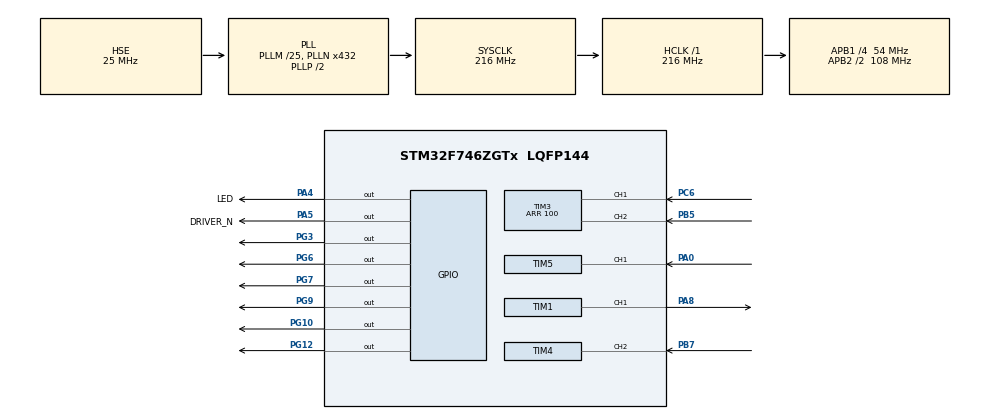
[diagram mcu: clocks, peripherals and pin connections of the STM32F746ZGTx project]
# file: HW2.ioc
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Mcu.Family=STM32F7
Mcu.Name=STM32F746ZGTx
Mcu.Package=LQFP144
NVIC.PriorityGroup=NVIC_PRIORITYGROUP_4
NVIC.TIM1_CC_IRQn=true\:0\:0\:false\:false\:true\:true\:true
NVIC.TIM1_UP_TIM10_IRQn=true\:0\:0\:false\:false\:true\:true\:true
NVIC.TIM2_IRQn=true\:0\:0\:false\:false\:true\:true\:true
NVIC.TIM4_IRQn=true\:0\:0\:false\:false\:true\:true\:true
NVIC.TIM5_IRQn=true\:0\:0\:false\:false\:true\:true\:true
PA0/WKUP.Signal=S_TIM5_CH1
PA4.GPIO_Label=LED
PA4.Signal=GPIO_Output
PA5.GPIO_Label=DRIVER_N
PA5.Signal=GPIO_Output
PA8.Signal=S_TIM1_CH1
PB5.Signal=S_TIM3_CH2
PB7.Signal=S_TIM4_CH2
PC6.Signal=S_TIM3_CH1
PG10.Signal=GPIO_Output
PG12.Signal=GPIO_Output
PG3.Signal=GPIO_Output
PG6.Signal=GPIO_Output
PG7.Signal=GPIO_Output
PG9.Signal=GPIO_Output
PH0/OSC_IN.Mode=HSE-External-Oscillator
PH0/OSC_IN.Signal=RCC_OSC_IN
PH1/OSC_OUT.Mode=HSE-External-Oscillator
PH1/OSC_OUT.Signal=RCC_OSC_OUT
ProjectManager.HeapSize=0x200
ProjectManager.StackSize=0x400
ProjectManager.TargetToolchain=MDK-ARM V5.27
RCC.AHBFreq_Value=216000000
RCC.APB1CLKDivider=RCC_HCLK_DIV4
RCC.APB1Freq_Value=54000000
RCC.APB1TimFreq_Value=108000000
RCC.APB2CLKDivider=RCC_HCLK_DIV2
RCC.APB2Freq_Value=108000000
RCC.APB2TimFreq_Value=216000000
RCC.CortexFreq_Value=216000000
RCC.HCLKFreq_Value=216000000
RCC.HSE_VALUE=25000000
RCC.HSI_VALUE=16000000
RCC.LSE_VALUE=32768
RCC.PLLM=25
RCC.PLLN=432
RCC.PLLSourceVirtual=RCC_PLLSOURCE_HSE
RCC.SYSCLKFreq_VALUE=216000000
RCC.SYSCLKSource=RCC_SYSCLKSOURCE_PLLCLK
RCC.USBFreq_Value=216000000
RCC.VCOOutputFreq_Value=432000000
SH.S_TIM1_CH1.0=TIM1_CH1,PWM Generation1 CH1
SH.S_TIM3_CH1.0=TIM3_CH1,Encoder_Interface
SH.S_TIM3_CH2.0=TIM3_CH2,Encoder_Interface
SH.S_TIM4_CH2.0=TIM4_CH2,Input_Capture2_from_TI2
SH.S_TIM5_CH1.0=TIM5_CH1,Input_Capture1_from_TI1
TIM1.AutoReloadPreload=TIM_AUTORELOAD_PRELOAD_DISABLE
TIM1.Channel-PWM\ Generation1\ CH1=TIM_CHANNEL_1
TIM1.Period=100-1
TIM1.Prescaler=108-1
TIM1.Pulse-PWM\ Generation1\ CH1=50
TIM2.Period=999
TIM2.Prescaler=10799
TIM3.AutoReloadPreload=TIM_AUTORELOAD_PRELOAD_ENABLE
TIM3.Period=100
TIM4.Channel-Input_Capture2_from_TI2=TIM_CHANNEL_2
TIM4.Period=40000-1
TIM4.Prescaler=1080-1
TIM5.Channel-Input_Capture1_from_TI1=TIM_CHANNEL_1
TIM5.Period=40000-1
TIM5.Prescaler=1080-1
VP_TIM1_VS_ClockSourceINT.Mode=Internal
VP_TIM2_VS_ClockSourceINT.Mode=Internal
VP_TIM4_VS_ClockSourceINT.Mode=Internal
VP_TIM5_VS_ClockSourceINT.Mode=Internal
board=custom

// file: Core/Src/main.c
/* USER CODE BEGIN Header */
/**
  ******************************************************************************
  * @file           : main.c
  * @brief          : Main program body
  ******************************************************************************
  * @attention
  *
  * <h2><center>&copy; Copyright (c) 2021 STMicroelectronics.
  * All rights reserved.</center></h2>
  *
  * This software component is licensed by ST under BSD 3-Clause license,
  * the "License"; You may not use this file except in compliance with the
  * License. You may obtain a copy of the License at:
  *                        opensource.org/licenses/BSD-3-Clause
  *
  ******************************************************************************
  */
/* USER CODE END Header */
#include "main.h"
#include "tim.h"
#include "gpio.h"

void SystemClock_Config(void);

int main(void)
{

  /* MCU Configuration--------------------------------------------------------*/

  /* Reset of all peripherals, Initializes the Flash interface and the Systick. */
  HAL_Init();

  /* Configure the system clock */
  SystemClock_Config();

  /* Initialize all configured peripherals */
  MX_GPIO_Init();
  MX_TIM1_Init();
  MX_TIM2_Init();
  MX_TIM3_Init();
  MX_TIM4_Init();
  MX_TIM5_Init();
  /* USER CODE BEGIN 2 */
	//HAL_TIM_Base_Start_IT(&htim1);
	HAL_TIM_Base_Start_IT(&htim5);
//Turn on input capture interrupt, set drop edge to trigger interrupt
//__HAL_TIM_SET_CAPTUREPOLARITY(&htim4, TIM_CHANNEL_2, TIM_INPUTCHANNELPOLARITY_RISING);
	HAL_TIM_IC_Start_IT(&htim5, TIM_CHANNEL_1);    //Start Input Capture
	HAL_TIM_Base_Start_IT(&htim4);
	HAL_TIM_IC_Start_IT(&htim4, TIM_CHANNEL_2);
	__HAL_TIM_CLEAR_IT(&htim3,TIM_IT_UPDATE);
	__HAL_TIM_ENABLE_IT(&htim3,TIM_IT_UPDATE);
	HAL_TIM_Base_Start_IT(&htim1);
	HAL_TIM_Base_Start_IT(&htim2);
	HAL_TIM_PWM_Start_IT(&htim1,TIM_CHANNEL_1);
	HAL_TIM_Encoder_Start(&htim3, TIM_CHANNEL_ALL);
	HAL_TIM_OC_Start_IT(&htim1,TIM_CHANNEL_1);
	//HAL_TIM_IC_Start_IT(&htim4,TIM_CHANNEL_2);
	HAL_GPIO_WritePin(DRIVER_N_GPIO_Port,DRIVER_N_Pin,GPIO_PIN_RESET);
  /* USER CODE END 2 */

  /* Infinite loop */
  while (1)
  {

    /* USER CODE BEGIN 3 */
//		HAL_GPIO_TogglePin(LED_GPIO_Port,LED_Pin);
//		HAL_Delay(500);
  }
  /* USER CODE END 3 */
}

void SystemClock_Config(void)
{
  RCC_OscInitTypeDef RCC_OscInitStruct = {0};
  RCC_ClkInitTypeDef RCC_ClkInitStruct = {0};

  /** Configure the main internal regulator output voltage
  */
  __HAL_RCC_PWR_CLK_ENABLE();
  __HAL_PWR_VOLTAGESCALING_CONFIG(PWR_REGULATOR_VOLTAGE_SCALE1);
  /** Initializes the RCC Oscillators according to the specified parameters
  * in the RCC_OscInitTypeDef structure.
  */
  RCC_OscInitStruct.OscillatorType = RCC_OSCILLATORTYPE_HSE;
  RCC_OscInitStruct.HSEState = RCC_HSE_ON;
  RCC_OscInitStruct.PLL.PLLState = RCC_PLL_ON;
  RCC_OscInitStruct.PLL.PLLSource = RCC_PLLSOURCE_HSE;
  RCC_OscInitStruct.PLL.PLLM = 25;
  RCC_OscInitStruct.PLL.PLLN = 432;
  RCC_OscInitStruct.PLL.PLLP = RCC_PLLP_DIV2;
  RCC_OscInitStruct.PLL.PLLQ = 2;
  if (HAL_RCC_OscConfig(&RCC_OscInitStruct) != HAL_OK)
  {
    Error_Handler();
  }
  /** Activate the Over-Drive mode
  */
  if (HAL_PWREx_EnableOverDrive() != HAL_OK)
  {
    Error_Handler();
  }
  /** Initializes the CPU, AHB and APB buses clocks
  */
  RCC_ClkInitStruct.ClockType = RCC_CLOCKTYPE_HCLK|RCC_CLOCKTYPE_SYSCLK
                              |RCC_CLOCKTYPE_PCLK1|RCC_CLOCKTYPE_PCLK2;
  RCC_ClkInitStruct.SYSCLKSource = RCC_SYSCLKSOURCE_PLLCLK;
  RCC_ClkInitStruct.AHBCLKDivider = RCC_SYSCLK_DIV1;
  RCC_ClkInitStruct.APB1CLKDivider = RCC_HCLK_DIV4;
  RCC_ClkInitStruct.APB2CLKDivider = RCC_HCLK_DIV2;

  if (HAL_RCC_ClockConfig(&RCC_ClkInitStruct, FLASH_LATENCY_7) != HAL_OK)
  {
    Error_Handler();
  }
}

void Error_Handler(void)
{
  __disable_irq();
  while (1)
  {
  }
}

/************************ (C) COPYRIGHT STMicroelectronics *****END OF FILE****/
